# CY8C4247LQI_BL483 register map
File version: 0.1
PSoC 4200 BLE
Registers are 32-bit, read-write, no defined reset value unless marked. A register's access mark holds for its fields unless they carry their own. Offsets are from the block's base; lines under a group give offsets from that group; [hi:lo] are bit positions; {n}, {i} and the like mark numbered series; 'fields as' and 'values as' point back to an identical list; <NAME> marks a mode.

## Memory map
0x00000000 Timer_uart
0x00000000 Timer_wire
0x00000000 UART

## Timer_uart
Base 0x00000000
0x40200148 COUNTER — Current counter value
0x4020014C CC — Compare / capture value
0x40200150 CC_BUF — Compare / capture buffer value
0x40200154 PERIOD — Period value
0x40200158 PERIOD_BUF — Period buffer value

## Timer_wire
Base 0x00000000
0x40200108 COUNTER — Current counter value
0x4020010C CC — Compare / capture value
0x40200110 CC_BUF — Compare / capture buffer value
0x40200114 PERIOD — Period value
0x40200118 PERIOD_BUF — Period buffer value

## UART
Base 0x00000000
0x400F0023 RX_UART_RX_ADDRESS1 8-bit — RX Address1 Register
0x400F0033 RX_UART_RX_ADDRESS2 8-bit — RX Address2 Register
0x400F0040 TX_UART_TX_DATA 8-bit — TX Data Register
0x400F0043 RX_UART_RX_DATA 8-bit — RX Data Register
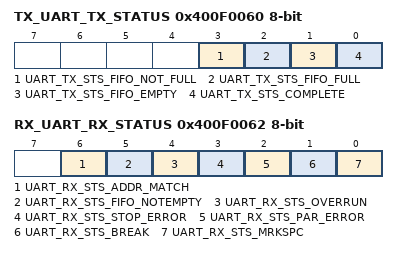
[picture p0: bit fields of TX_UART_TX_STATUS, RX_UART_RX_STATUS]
0x400F0060 TX_UART_TX_STATUS 8-bit — TX status register
  [3] UART_TX_STS_FIFO_NOT_FULL ro, [2] UART_TX_STS_FIFO_FULL ro, [1] UART_TX_STS_FIFO_EMPTY ro, [0] UART_TX_STS_COMPLETE ro
0x400F0062 RX_UART_RX_STATUS 8-bit — RX status register
  [6] UART_RX_STS_ADDR_MATCH ro, [5] UART_RX_STS_FIFO_NOTEMPTY ro, [4] UART_RX_STS_OVERRUN ro, [3] UART_RX_STS_STOP_ERROR ro, [2] UART_RX_STS_PAR_ERROR ro, [1] UART_RX_STS_BREAK ro, [0] UART_RX_STS_MRKSPC ro
